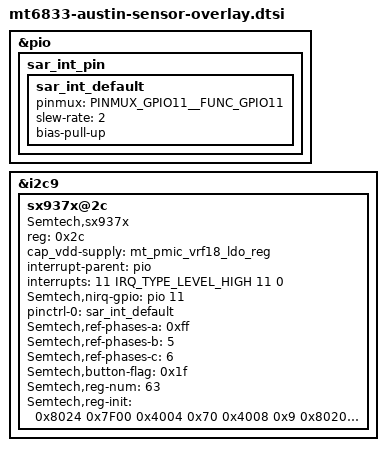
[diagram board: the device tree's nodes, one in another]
&pio {
	sar_int_pin {
		sar_int_default: sar_int_default {
		/* active state */
		pinmux = <PINMUX_GPIO11__FUNC_GPIO11>;
		slew-rate = <2>;
		bias-pull-up;
		};
	};
};

&i2c9 {
	    sx937x@2c {
		compatible = "Semtech,sx937x";
		status = "okay";
		reg = <0x2c>;
		cap_vdd-supply = <&mt_pmic_vrf18_ldo_reg>;
		interrupt-parent = <&pio>;
		interrupts = <11 IRQ_TYPE_LEVEL_HIGH 11 0>;
		Semtech,nirq-gpio = <&pio 11 0x0>;
		pinctrl-names = "sar_int_default";
		pinctrl-0 = <&sar_int_default>;
		/*use PH3/4 as the reference sensor
		set it to 0xff if the ref-phases-x is not used*/
		Semtech,ref-phases-a = <0xff>;
		Semtech,ref-phases-b = <5>;
		Semtech,ref-phases-c = <6>;
		Semtech,button-flag = <0x1f>;
		Semtech,reg-num = <63>;
		Semtech,reg-init = <
			0x8024 0x7F00
			0x4004 0x70
			0x4008 0x9
			0x8020 0x32
			0x8028 0x876
			0x8034 0x876
			0x8040 0x876
			0x804C 0x876
			0x8058 0x876
			0x8064 0x876
			0x8070 0x876
			0x807C 0x85C
			0x8030 0xFFD9FF
			0x803C 0xFEF9FF
			0x8048 0xFFF9FD
			0x8054 0xF7F9FF
			0x8060 0xBFF9FF
			0x806C 0xFFF97F
			0x8078 0xFFF9EF
			0x8084 0xBFF9FF
			0x8098 0x6942
			0x80B8 0x3E3E
			0x80D8 0x5A39
			0x80F8 0x3B3B
			0x8118 0x5858
			0x8138 0x8E
			0x8158 0x8E
			0x80A0 0x1E1E00E1
			0x80C0 0x101000E2
			0x80E0 0xB0B00E2
			0x8100 0xD0D00E2
			0x8120 0x181800E2
			0x8140 0x0
			0x8160 0x0
			0x8180 0x0
			0x8188 0x8000015
			0x818C 0x8000016
			0x8190 0x0
			0x8194 0x0
			0x8090 0x64B45000
			0x80B0 0x3CD05000
			0x80D0 0x32D87000
			0x80F0 0x3CD45000
			0x8110 0x3CD47000
			0x8130 0x54AC5000
			0x8150 0x54AC5000
			0x8170 0x54AC5000
			0x8088 0x300000
			0x80A8 0x300000
			0x80C8 0x300000
			0x80E8 0x300000
			0x8108 0x300000
			0x8128 0x600000
			0x8148 0x600000
			0x808C 0x60200030
			0x80AC 0x60200030
			0x80CC 0x60200018
			0x80EC 0x60200030
			0x810C 0x60200018
			0x812C 0x60200030
			0x814C 0x60200030
			0x816C 0x60200030
			0x8024 0x7F7F>;
	};
};
